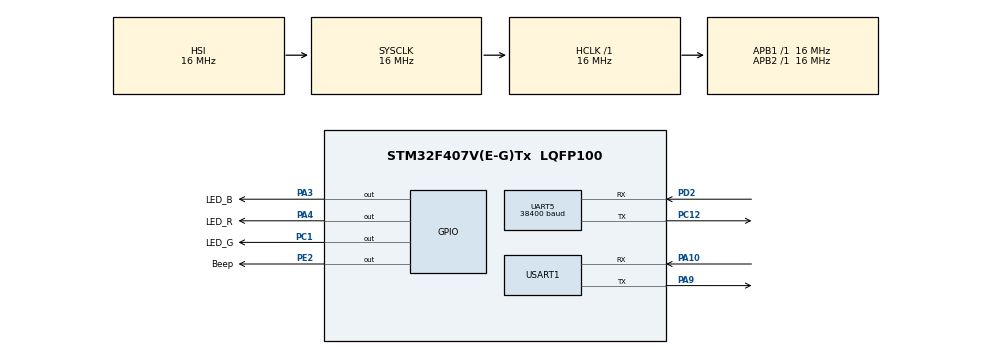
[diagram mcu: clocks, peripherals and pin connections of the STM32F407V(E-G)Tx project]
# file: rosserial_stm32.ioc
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Mcu.Family=STM32F4
Dma.UART5_TX.3.MemDataAlignment=DMA_MDATAALIGN_BYTE
RCC.CortexFreq_Value=16000000
Dma.UART5_RX.2.Instance=DMA1_Stream0
Dma.USART1_TX.1.MemInc=DMA_MINC_ENABLE
PC12.Signal=UART5_TX
PA3.GPIO_PuPd=GPIO_PULLUP
PE2.GPIO_Speed=GPIO_SPEED_FREQ_HIGH
PA3.GPIO_Speed=GPIO_SPEED_FREQ_HIGH
Dma.UART5_TX.3.Direction=DMA_MEMORY_TO_PERIPH
ProjectManager.StackSize=0x400
NVIC.UART5_IRQn=true\:0\:0\:false\:false\:true\:true\:true
Dma.UART5_TX.3.MemInc=DMA_MINC_ENABLE
RCC.HCLKFreq_Value=16000000
RCC.APB2TimFreq_Value=16000000
Dma.UART5_TX.3.FIFOMode=DMA_FIFOMODE_DISABLE
PC1.PinState=GPIO_PIN_SET
RCC.AHBFreq_Value=16000000
Dma.USART1_RX.0.Priority=DMA_PRIORITY_HIGH
RCC.HSE_VALUE=25000000
PA4.GPIO_PuPd=GPIO_PULLUP
PC1.GPIO_PuPd=GPIO_PULLUP
PA4.GPIO_Speed=GPIO_SPEED_FREQ_HIGH
PA14.Mode=Serial_Wire
Dma.UART5_RX.2.Priority=DMA_PRIORITY_MEDIUM
PE2.Signal=GPIO_Output
Dma.UART5_TX.3.Priority=DMA_PRIORITY_MEDIUM
Dma.USART1_RX.0.MemInc=DMA_MINC_ENABLE
Dma.UART5_RX.2.PeriphInc=DMA_PINC_DISABLE
Dma.USART1_TX.1.PeriphDataAlignment=DMA_PDATAALIGN_BYTE
NVIC.DMA1_Stream7_IRQn=true\:0\:0\:false\:false\:true\:false\:true
Mcu.Package=LQFP100
NVIC.DMA2_Stream7_IRQn=true\:0\:0\:false\:false\:true\:false\:true
PA10.Signal=USART1_RX
Dma.USART1_RX.0.FIFOMode=DMA_FIFOMODE_DISABLE
NVIC.DMA2_Stream2_IRQn=true\:0\:0\:false\:false\:true\:false\:true
Dma.Request2=UART5_RX
Dma.Request1=USART1_TX
RCC.APB1TimFreq_Value=16000000
Dma.Request3=UART5_TX
Dma.USART1_RX.0.Mode=DMA_CIRCULAR
Dma.USART1_TX.1.Priority=DMA_PRIORITY_HIGH
NVIC.DMA1_Stream0_IRQn=true\:0\:0\:false\:false\:true\:false\:true
UART5.BaudRate=38400
NVIC.USART1_IRQn=true\:0\:0\:false\:false\:true\:true\:true
Dma.Request0=USART1_RX
PA4.GPIO_Label=LED_R
PE2.GPIO_Label=Beep
Dma.USART1_RX.0.Instance=DMA2_Stream2
Dma.UART5_RX.2.FIFOMode=DMA_FIFOMODE_DISABLE
PA3.Signal=GPIO_Output
Dma.UART5_TX.3.Mode=DMA_NORMAL
Dma.USART1_TX.1.Direction=DMA_MEMORY_TO_PERIPH
Dma.USART1_TX.1.Instance=DMA2_Stream7
Dma.USART1_RX.0.PeriphDataAlignment=DMA_PDATAALIGN_BYTE
PA10.Mode=Asynchronous
Dma.UART5_TX.3.PeriphDataAlignment=DMA_PDATAALIGN_BYTE
UART5.VirtualMode=Asynchronous
Dma.UART5_RX.2.MemInc=DMA_MINC_ENABLE
Dma.UART5_TX.3.Instance=DMA1_Stream7
PA13.Signal=SYS_JTMS-SWDIO
PA9.Mode=Asynchronous
PA4.PinState=GPIO_PIN_SET
ProjectManager.TargetToolchain=STM32CubeIDE
Dma.USART1_RX.0.Direction=DMA_PERIPH_TO_MEMORY
PA9.Signal=USART1_TX
Dma.USART1_TX.1.FIFOMode=DMA_FIFOMODE_DISABLE
RCC.LSE_VALUE=32768
Dma.USART1_RX.0.PeriphInc=DMA_PINC_DISABLE
PD2.Mode=Asynchronous
PE2.GPIO_PuPd=GPIO_PULLUP
PC12.Mode=Asynchronous
Dma.USART1_TX.1.MemDataAlignment=DMA_MDATAALIGN_BYTE
board=custom
RCC.VCOOutputFreq_Value=192000000
RCC.APB2Freq_Value=16000000
PC1.GPIO_Label=LED_G
Dma.USART1_RX.0.MemDataAlignment=DMA_MDATAALIGN_BYTE
PC1.GPIO_Speed=GPIO_SPEED_FREQ_HIGH
PA13.Mode=Serial_Wire
Mcu.Name=STM32F407V(E-G)Tx
PA4.Signal=GPIO_Output
RCC.SYSCLKFreq_VALUE=16000000
Dma.USART1_TX.1.Mode=DMA_NORMAL
Dma.UART5_TX.3.PeriphInc=DMA_PINC_DISABLE
USART1.VirtualMode=VM_ASYNC
PA14.Signal=SYS_JTCK-SWCLK
ProjectManager.HeapSize=0x200
Dma.UART5_RX.2.Mode=DMA_NORMAL
Dma.USART1_TX.1.PeriphInc=DMA_PINC_DISABLE
RCC.HSI_VALUE=16000000
NVIC.PriorityGroup=NVIC_PRIORITYGROUP_4
Dma.UART5_RX.2.Direction=DMA_PERIPH_TO_MEMORY
PA3.PinState=GPIO_PIN_SET
PD2.Signal=UART5_RX
RCC.APB1Freq_Value=16000000
PC1.Signal=GPIO_Output
Dma.UART5_RX.2.PeriphDataAlignment=DMA_PDATAALIGN_BYTE
Dma.UART5_RX.2.MemDataAlignment=DMA_MDATAALIGN_BYTE
PA3.GPIO_Label=LED_B

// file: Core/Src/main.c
/* USER CODE BEGIN Header */
/**
  ******************************************************************************
  * @file           : main.c
  * @brief          : Main program body
  ******************************************************************************
  * @attention
  *
  * <h2><center>&copy; Copyright (c) 2021 STMicroelectronics.
  * All rights reserved.</center></h2>
  *
  * This software component is licensed by ST under BSD 3-Clause license,
  * the "License"; You may not use this file except in compliance with the
  * License. You may obtain a copy of the License at:
  *                        opensource.org/licenses/BSD-3-Clause
  *
  ******************************************************************************
  */
/* USER CODE END Header */
#include "main.h"

/* USER CODE BEGIN Includes */
#include "mainpp.h"

/* USER CODE END Includes */

/* USER CODE BEGIN PM */
#ifdef __GNUC__
/* With GCC, small printf (option LD Linker->Libraries->Small printf
   set to 'Yes') calls __io_putchar() */
#define PUTCHAR_PROTOTYPE int __io_putchar(int ch)
#else
#define PUTCHAR_PROTOTYPE int fputc(int ch, FILE *f)
#endif /* __GNUC__ */

/* USER CODE END PM */

UART_HandleTypeDef huart5;
UART_HandleTypeDef huart1;
DMA_HandleTypeDef hdma_uart5_rx;
DMA_HandleTypeDef hdma_uart5_tx;
DMA_HandleTypeDef hdma_usart1_rx;
DMA_HandleTypeDef hdma_usart1_tx;

/* USER CODE BEGIN PV */
UART_HandleTypeDef *rosserial_huart = &huart1;
UART_HandleTypeDef *motorDriver_huart = &huart5;

/* USER CODE END PV */

void SystemClock_Config(void);
static void MX_GPIO_Init(void);
static void MX_DMA_Init(void);
static void MX_USART1_UART_Init(void);
static void MX_UART5_Init(void);

int main(void)
{

  /* MCU Configuration--------------------------------------------------------*/

  /* Reset of all peripherals, Initializes the Flash interface and the Systick. */
  HAL_Init();

  /* Configure the system clock */
  SystemClock_Config();

  /* Initialize all configured peripherals */
  MX_GPIO_Init();
  MX_DMA_Init();
  MX_USART1_UART_Init();
  MX_UART5_Init();
  /* USER CODE BEGIN 2 */
  setup();
  printf("**********rosserial on STM32 start************\n\r");
  /* USER CODE END 2 */

  /* Infinite loop */
  /* USER CODE BEGIN WHILE */
  while (1)
  {
	  //printf("Hello rosserial\n\r");
	  //HAL_Delay(1000);
	  //HAL_UART_Transmit_DMA(&huart1, (uint8_t *)"Hello rosserial\n\r", 17);
	  loop();
    /* USER CODE END WHILE */

  }
}

void SystemClock_Config(void)
{
  RCC_OscInitTypeDef RCC_OscInitStruct = {0};
  RCC_ClkInitTypeDef RCC_ClkInitStruct = {0};

  /** Configure the main internal regulator output voltage
  */
  __HAL_RCC_PWR_CLK_ENABLE();
  __HAL_PWR_VOLTAGESCALING_CONFIG(PWR_REGULATOR_VOLTAGE_SCALE1);
  /** Initializes the RCC Oscillators according to the specified parameters
  * in the RCC_OscInitTypeDef structure.
  */
  RCC_OscInitStruct.OscillatorType = RCC_OSCILLATORTYPE_HSI;
  RCC_OscInitStruct.HSIState = RCC_HSI_ON;
  RCC_OscInitStruct.HSICalibrationValue = RCC_HSICALIBRATION_DEFAULT;
  RCC_OscInitStruct.PLL.PLLState = RCC_PLL_NONE;
  if (HAL_RCC_OscConfig(&RCC_OscInitStruct) != HAL_OK)
  {
    Error_Handler();
  }
  /** Initializes the CPU, AHB and APB buses clocks
  */
  RCC_ClkInitStruct.ClockType = RCC_CLOCKTYPE_HCLK|RCC_CLOCKTYPE_SYSCLK
                              |RCC_CLOCKTYPE_PCLK1|RCC_CLOCKTYPE_PCLK2;
  RCC_ClkInitStruct.SYSCLKSource = RCC_SYSCLKSOURCE_HSI;
  RCC_ClkInitStruct.AHBCLKDivider = RCC_SYSCLK_DIV1;
  RCC_ClkInitStruct.APB1CLKDivider = RCC_HCLK_DIV1;
  RCC_ClkInitStruct.APB2CLKDivider = RCC_HCLK_DIV1;

  if (HAL_RCC_ClockConfig(&RCC_ClkInitStruct, FLASH_LATENCY_0) != HAL_OK)
  {
    Error_Handler();
  }
}

static void MX_UART5_Init(void)
{

  huart5.Instance = UART5;
  huart5.Init.BaudRate = 38400;
  huart5.Init.WordLength = UART_WORDLENGTH_8B;
  huart5.Init.StopBits = UART_STOPBITS_1;
  huart5.Init.Parity = UART_PARITY_NONE;
  huart5.Init.Mode = UART_MODE_TX_RX;
  huart5.Init.HwFlowCtl = UART_HWCONTROL_NONE;
  huart5.Init.OverSampling = UART_OVERSAMPLING_16;
  if (HAL_UART_Init(&huart5) != HAL_OK)
  {
    Error_Handler();
  }

}

static void MX_USART1_UART_Init(void)
{

  huart1.Instance = USART1;
  huart1.Init.BaudRate = 115200;
  huart1.Init.WordLength = UART_WORDLENGTH_8B;
  huart1.Init.StopBits = UART_STOPBITS_1;
  huart1.Init.Parity = UART_PARITY_NONE;
  huart1.Init.Mode = UART_MODE_TX_RX;
  huart1.Init.HwFlowCtl = UART_HWCONTROL_NONE;
  huart1.Init.OverSampling = UART_OVERSAMPLING_16;
  if (HAL_UART_Init(&huart1) != HAL_OK)
  {
    Error_Handler();
  }

}

static void MX_DMA_Init(void)
{

  /* DMA controller clock enable */
  __HAL_RCC_DMA2_CLK_ENABLE();
  __HAL_RCC_DMA1_CLK_ENABLE();

  /* DMA interrupt init */
  /* DMA1_Stream0_IRQn interrupt configuration */
  HAL_NVIC_SetPriority(DMA1_Stream0_IRQn, 0, 0);
  HAL_NVIC_EnableIRQ(DMA1_Stream0_IRQn);
  /* DMA1_Stream7_IRQn interrupt configuration */
  HAL_NVIC_SetPriority(DMA1_Stream7_IRQn, 0, 0);
  HAL_NVIC_EnableIRQ(DMA1_Stream7_IRQn);
  /* DMA2_Stream2_IRQn interrupt configuration */
  HAL_NVIC_SetPriority(DMA2_Stream2_IRQn, 0, 0);
  HAL_NVIC_EnableIRQ(DMA2_Stream2_IRQn);
  /* DMA2_Stream7_IRQn interrupt configuration */
  HAL_NVIC_SetPriority(DMA2_Stream7_IRQn, 0, 0);
  HAL_NVIC_EnableIRQ(DMA2_Stream7_IRQn);

}

static void MX_GPIO_Init(void)
{
  GPIO_InitTypeDef GPIO_InitStruct = {0};

  /* GPIO Ports Clock Enable */
  __HAL_RCC_GPIOE_CLK_ENABLE();
  __HAL_RCC_GPIOC_CLK_ENABLE();
  __HAL_RCC_GPIOA_CLK_ENABLE();
  __HAL_RCC_GPIOD_CLK_ENABLE();

  /*Configure GPIO pin Output Level */
  HAL_GPIO_WritePin(Beep_GPIO_Port, Beep_Pin, GPIO_PIN_RESET);

  /*Configure GPIO pin Output Level */
  HAL_GPIO_WritePin(LED_G_GPIO_Port, LED_G_Pin, GPIO_PIN_SET);

  /*Configure GPIO pin Output Level */
  HAL_GPIO_WritePin(GPIOA, LED_B_Pin|LED_R_Pin, GPIO_PIN_SET);

  /*Configure GPIO pin : Beep_Pin */
  GPIO_InitStruct.Pin = Beep_Pin;
  GPIO_InitStruct.Mode = GPIO_MODE_OUTPUT_PP;
  GPIO_InitStruct.Pull = GPIO_PULLUP;
  GPIO_InitStruct.Speed = GPIO_SPEED_FREQ_HIGH;
  HAL_GPIO_Init(Beep_GPIO_Port, &GPIO_InitStruct);

  /*Configure GPIO pin : LED_G_Pin */
  GPIO_InitStruct.Pin = LED_G_Pin;
  GPIO_InitStruct.Mode = GPIO_MODE_OUTPUT_PP;
  GPIO_InitStruct.Pull = GPIO_PULLUP;
  GPIO_InitStruct.Speed = GPIO_SPEED_FREQ_HIGH;
  HAL_GPIO_Init(LED_G_GPIO_Port, &GPIO_InitStruct);

  /*Configure GPIO pins : LED_B_Pin LED_R_Pin */
  GPIO_InitStruct.Pin = LED_B_Pin|LED_R_Pin;
  GPIO_InitStruct.Mode = GPIO_MODE_OUTPUT_PP;
  GPIO_InitStruct.Pull = GPIO_PULLUP;
  GPIO_InitStruct.Speed = GPIO_SPEED_FREQ_HIGH;
  HAL_GPIO_Init(GPIOA, &GPIO_InitStruct);

}

/* USER CODE BEGIN 4 */
/**
  * @brief  Retargets the C library printf function to the USART.
  * @param  None
  * @retval None
  */
PUTCHAR_PROTOTYPE
{
  /* Place your implementation of fputc here */
  /* e.g. write a character to the USART1 and Loop until the end of transmission */
  HAL_UART_Transmit(&huart1, (uint8_t *)&ch, 1, 0xFFFF);

  return ch;
}

/* USER CODE END 4 */

void Error_Handler(void)
{
  __disable_irq();
  while (1)
  {
  }
}

/************************ (C) COPYRIGHT STMicroelectronics *****END OF FILE****/
